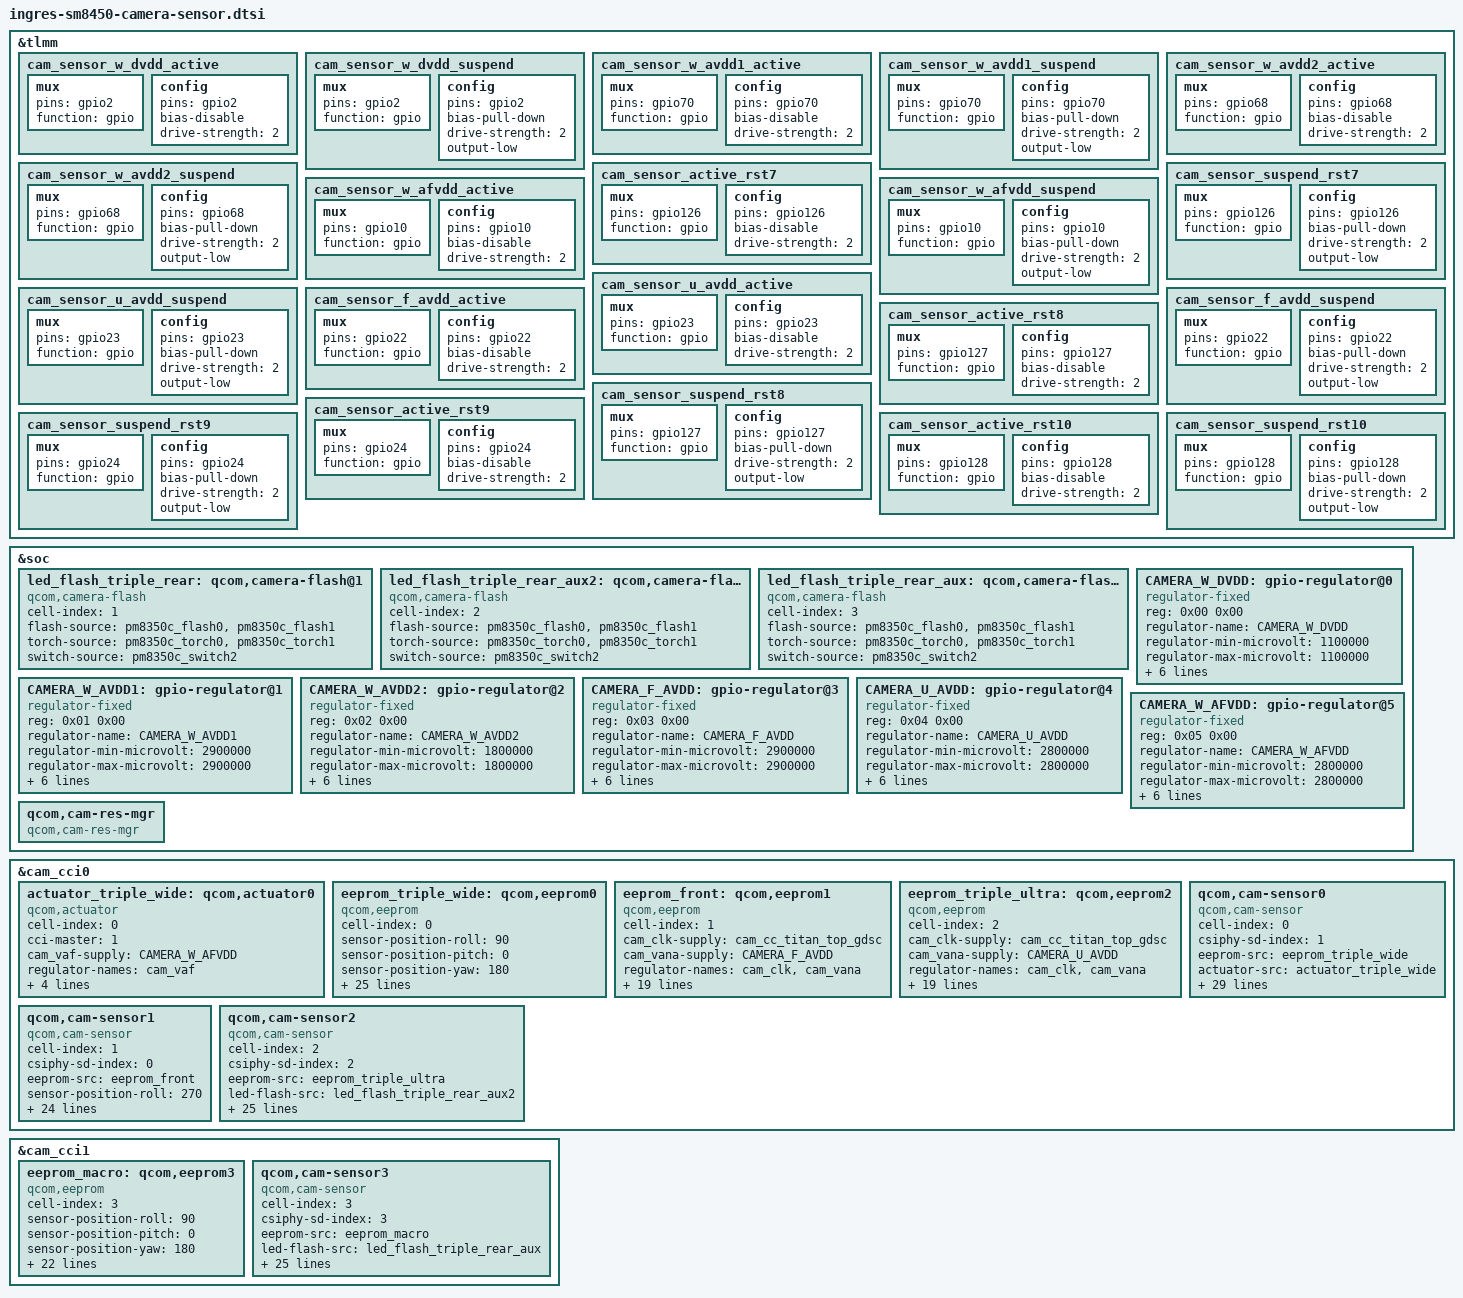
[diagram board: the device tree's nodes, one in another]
#include <dt-bindings/clock/qcom,camcc-waipio.h>

&tlmm {
//wide dvdd
	cam_sensor_w_dvdd_active: cam_sensor_w_dvdd_active {
		/* SENSOR WIDE DVDD ENABLE */
		mux {
			pins = "gpio2";
			function = "gpio";
		};

		config {
			pins = "gpio2";
			bias-disable; /* No PULL */
			drive-strength = <2>; /* 2 MA */
		};
	};

	cam_sensor_w_dvdd_suspend: cam_sensor_w_dvdd_suspend {
		/* SENSOR WIDE DVDD DISABLE */
		mux {
			pins = "gpio2";
			function = "gpio";
		};

		config {
			pins = "gpio2";
			bias-pull-down; /* PULL DOWN */
			drive-strength = <2>; /* 2 MA */
			output-low;
		};
	};

//wide avdd1
	cam_sensor_w_avdd1_active: cam_sensor_w_avdd1_active {
		/* SENSOR WIDE DVDD ENABLE */
		mux {
			pins = "gpio70";
			function = "gpio";
		};

		config {
			pins = "gpio70";
			bias-disable; /* No PULL */
			drive-strength = <2>; /* 2 MA */
		};
	};

	cam_sensor_w_avdd1_suspend: cam_sensor_w_avdd1_suspend {
		/* SENSOR WIDE DVDD DISABLE */
		mux {
			pins = "gpio70";
			function = "gpio";
		};

		config {
			pins = "gpio70";
			bias-pull-down; /* PULL DOWN */
			drive-strength = <2>; /* 2 MA */
			output-low;
		};
	};

//wide avdd2
	cam_sensor_w_avdd2_active: cam_sensor_w_avdd2_active {
		/* SENSOR WIDE DVDD ENABLE */
		mux {
			pins = "gpio68";
			function = "gpio";
		};

		config {
			pins = "gpio68";
			bias-disable; /* No PULL */
			drive-strength = <2>; /* 2 MA */
		};
	};

	cam_sensor_w_avdd2_suspend: cam_sensor_w_avdd2_suspend {
		/* SENSOR WIDE DVDD DISABLE */
		mux {
			pins = "gpio68";
			function = "gpio";
		};

		config {
			pins = "gpio68";
			bias-pull-down; /* PULL DOWN */
			drive-strength = <2>; /* 2 MA */
			output-low;
		};
	};

//wide reset
	cam_sensor_active_rst7: cam_sensor_active_rst7 {
		/* RESET FRONT */
		mux {
			pins = "gpio126";
			function = "gpio";
		};

		config {
			pins = "gpio126";
			bias-disable; /* No PULL */
			drive-strength = <2>; /* 2 MA */
		};
	};

	cam_sensor_suspend_rst7: cam_sensor_suspend_rst7 {
		/* RESET FRONT */
		mux {
			pins = "gpio126";
			function = "gpio";
		};

		config {
			pins = "gpio126";
			bias-pull-down; /* PULL DOWN */
			drive-strength = <2>; /* 2 MA */
			output-low;
		};
	};
//wide  afvdd
	cam_sensor_w_afvdd_active: cam_sensor_w_afvdd_active {
		/* SENSOR FRONT DVDD ENABLE */
		mux {
			pins = "gpio10";
			function = "gpio";
		};

		config {
			pins = "gpio10";
			bias-disable; /* No PULL */
			drive-strength = <2>; /* 2 MA */
		};
	};

	cam_sensor_w_afvdd_suspend: cam_sensor_w_afvdd_suspend {
		/* SENSOR FRONT DVDD DISABLE */
		mux {
			pins = "gpio10";
			function = "gpio";
		};

		config {
			pins = "gpio10";
			bias-pull-down; /* PULL DOWN */
			drive-strength = <2>; /* 2 MA */
			output-low;
		};
	};
	
//front dvdd
	cam_sensor_u_avdd_active: cam_sensor_u_avdd_active {
		/* SENSOR FRONT DVDD ENABLE */
		mux {
			pins = "gpio23";
			function = "gpio";
		};

		config {
			pins = "gpio23";
			bias-disable; /* No PULL */
			drive-strength = <2>; /* 2 MA */
		};
	};

	cam_sensor_u_avdd_suspend: cam_sensor_u_avdd_suspend {
		/* SENSOR FRONT DVDD DISABLE */
		mux {
			pins = "gpio23";
			function = "gpio";
		};

		config {
			pins = "gpio23";
			bias-pull-down; /* PULL DOWN */
			drive-strength = <2>; /* 2 MA */
			output-low;
		};
	};

//front avdd
	cam_sensor_f_avdd_active: cam_sensor_f_avdd_active {
		/* SENSOR FRONT AVDD ENABLE */
		mux {
			pins = "gpio22";
			function = "gpio";
		};

		config {
			pins = "gpio22";
			bias-disable; /* No PULL */
			drive-strength = <2>; /* 2 MA */
		};
	};

	cam_sensor_f_avdd_suspend: cam_sensor_f_avdd_suspend {
		/* SENSOR FRONT AVDD DISABLE */
		mux {
			pins = "gpio22";
			function = "gpio";
		};

		config {
			pins = "gpio22";
			bias-pull-down; /* PULL DOWN */
			drive-strength = <2>; /* 2 MA */
			output-low;
		};
	};

//front reset
	cam_sensor_active_rst8: cam_sensor_active_rst8 {
		/* RESET FRONT */
		mux {
			pins = "gpio127";
			function = "gpio";
		};

		config {
			pins = "gpio127";
			bias-disable; /* No PULL */
			drive-strength = <2>; /* 2 MA */
		};
	};

	cam_sensor_suspend_rst8: cam_sensor_suspend_rst8 {
		/* RESET FRONT */
		mux {
			pins = "gpio127";
			function = "gpio";
		};

		config {
			pins = "gpio127";
			bias-pull-down; /* PULL DOWN */
			drive-strength = <2>; /* 2 MA */
			output-low;
		};
	};

//ultra reset
	cam_sensor_active_rst9: cam_sensor_active_rst9 {
		/* RESET FRONT */
		mux {
			pins = "gpio24";
			function = "gpio";
		};

		config {
			pins = "gpio24";
			bias-disable; /* No PULL */
			drive-strength = <2>; /* 2 MA */
		};
	};

	cam_sensor_suspend_rst9: cam_sensor_suspend_rst9 {
		/* RESET FRONT */
		mux {
			pins = "gpio24";
			function = "gpio";
		};

		config {
			pins = "gpio24";
			bias-pull-down; /* PULL DOWN */
			drive-strength = <2>; /* 2 MA */
			output-low;
		};
	};

//macro reset
	cam_sensor_active_rst10: cam_sensor_active_rst10 {
		/* RESET REARAUX */
		mux {
			pins = "gpio128";
			function = "gpio";
		};

		config {
			pins = "gpio128";
			bias-disable; /* No PULL */
			drive-strength = <2>; /* 2 MA */
		};
	};

	cam_sensor_suspend_rst10: cam_sensor_suspend_rst10 {
		/* RESET REARAUX */
		mux {
			pins = "gpio128";
			function = "gpio";
		};

		config {
			pins = "gpio128";
			bias-pull-down; /* PULL DOWN */
			drive-strength = <2>; /* 2 MA */
			output-low;
		};
	};
};

&soc {
	led_flash_triple_rear: qcom,camera-flash@1 {
		cell-index = <1>;
		compatible = "qcom,camera-flash";
		flash-source = <&pm8350c_flash0 &pm8350c_flash1>;
		torch-source = <&pm8350c_torch0 &pm8350c_torch1>;
		switch-source = <&pm8350c_switch2>;
		status = "ok";
	};

	led_flash_triple_rear_aux2: qcom,camera-flash@2 {
		cell-index = <2>;
		compatible = "qcom,camera-flash";
		flash-source = <&pm8350c_flash0 &pm8350c_flash1>;
		torch-source = <&pm8350c_torch0 &pm8350c_torch1>;
		switch-source = <&pm8350c_switch2>;
		status = "ok";
	};

	led_flash_triple_rear_aux: qcom,camera-flash@3 {
		cell-index = <3>;
		compatible = "qcom,camera-flash";
		flash-source = <&pm8350c_flash0 &pm8350c_flash1>;
		torch-source = <&pm8350c_torch0 &pm8350c_torch1>;
		switch-source = <&pm8350c_switch2>;
		status = "ok";
	};


	CAMERA_W_DVDD: gpio-regulator@0 {
		compatible = "regulator-fixed";
		reg = <0x00 0x00>;
		regulator-name = "CAMERA_W_DVDD";
		regulator-min-microvolt = <1100000>;
		regulator-max-microvolt = <1100000>;
		regulator-enable-ramp-delay = <100>;
		enable-active-high;
		gpio = <&tlmm 2 0>;
		pinctrl-names = "default", "sleep";
		pinctrl-0 = <&cam_sensor_w_dvdd_active &cam_sensor_w_dvdd_suspend>;
		vin-supply = <&S12B>;
	};

	CAMERA_W_AVDD1: gpio-regulator@1 {
		compatible = "regulator-fixed";
		reg = <0x01 0x00>;
		regulator-name = "CAMERA_W_AVDD1";
		regulator-min-microvolt = <2900000>;
		regulator-max-microvolt = <2900000>;
		regulator-enable-ramp-delay = <100>;
		enable-active-high;
		gpio = <&tlmm 70 0>;
		pinctrl-names = "default", "sleep";
		pinctrl-0 = <&cam_sensor_w_avdd1_active &cam_sensor_w_avdd1_suspend>;
		vin-supply = <&BOB>;
	};

	CAMERA_W_AVDD2: gpio-regulator@2 {
		compatible = "regulator-fixed";
		reg = <0x02 0x00>;
		regulator-name = "CAMERA_W_AVDD2";
		regulator-min-microvolt = <1800000>;
		regulator-max-microvolt = <1800000>;
		regulator-enable-ramp-delay = <100>;
		enable-active-high;
		gpio = <&tlmm 68 0>;
		pinctrl-names = "default", "sleep";
		pinctrl-0 = <&cam_sensor_w_avdd2_active &cam_sensor_w_avdd2_suspend>;
		vin-supply = <&BOB>;
	};

	CAMERA_F_AVDD: gpio-regulator@3 {
		compatible = "regulator-fixed";
		reg = <0x03 0x00>;
		regulator-name = "CAMERA_F_AVDD";
		regulator-min-microvolt = <2900000>;
		regulator-max-microvolt = <2900000>;
		regulator-enable-ramp-delay = <100>;
		enable-active-high;
		gpio = <&tlmm 22 0>;
		pinctrl-names = "default", "sleep";
		pinctrl-0 = <&cam_sensor_f_avdd_active &cam_sensor_f_avdd_suspend>;
		vin-supply = <&BOB>;
	};

	CAMERA_U_AVDD: gpio-regulator@4 {
		compatible = "regulator-fixed";
		reg = <0x04 0x00>;
		regulator-name = "CAMERA_U_AVDD";
		regulator-min-microvolt = <2800000>;
		regulator-max-microvolt = <2800000>;
		regulator-enable-ramp-delay = <100>;
		enable-active-high;
		gpio = <&tlmm 23 0>;
		pinctrl-names = "default", "sleep";
		pinctrl-0 = <&cam_sensor_u_avdd_active &cam_sensor_u_avdd_suspend>;
		vin-supply = <&BOB>;
	};

	CAMERA_W_AFVDD: gpio-regulator@5 {
		compatible = "regulator-fixed";
		reg = <0x05 0x00>;
		regulator-name = "CAMERA_W_AFVDD";
		regulator-min-microvolt = <2800000>;
		regulator-max-microvolt = <2800000>;
		regulator-enable-ramp-delay = <100>;
		enable-active-high;
		gpio = <&tlmm 10 0>;
		pinctrl-names = "default", "sleep";
		pinctrl-0 = <&cam_sensor_w_afvdd_active &cam_sensor_w_afvdd_suspend>;
		vin-supply = <&BOB>;
	};

	qcom,cam-res-mgr {
		compatible = "qcom,cam-res-mgr";
		status = "ok";
	};
};

&cam_cci0
{
	actuator_triple_wide: qcom,actuator0 {
		cell-index = <0>;
		compatible = "qcom,actuator";
		cci-master = <1>;
		cam_vaf-supply = <&CAMERA_W_AFVDD>;
		regulator-names = "cam_vaf";
		rgltr-cntrl-support;
		rgltr-min-voltage = <2800000>;
		rgltr-max-voltage = <2800000>;
		rgltr-load-current = <103000>;
	};

	eeprom_triple_wide:qcom,eeprom0 {
		cell-index = <0>;
		compatible = "qcom,eeprom";
		sensor-position-roll = <90>;
		sensor-position-pitch = <0>;
		sensor-position-yaw = <180>;
		//cam_vio-supply = <&L5J>;
		cam_vdig-supply = <&CAMERA_W_DVDD>;
		cam_clk-supply = <&cam_cc_titan_top_gdsc>;
		cam_vana-supply = <&CAMERA_W_AVDD1>;
		cam_v_custom1-supply = <&CAMERA_W_AVDD2>;
		regulator-names = "cam_vdig",
			"cam_clk", "cam_vana", "cam_v_custom1";
		rgltr-cntrl-support;
		rgltr-min-voltage = <1100000 0 2900000 1800000>;
		rgltr-max-voltage = <1100000 0 2900000 1800000>;
		rgltr-load-current = <872000 0 100000 100000>;
		gpio-no-mux = <0>;
		pinctrl-names = "cam_default", "cam_suspend";
		pinctrl-0 = <&cam_sensor_mclk2_active
			&cam_sensor_active_rst7>;
		pinctrl-1 = <&cam_sensor_mclk2_suspend
			&cam_sensor_suspend_rst7>;
		gpios = <&tlmm 102 0>,
			<&tlmm 126 0>;
		gpio-reset = <1>;
		gpio-req-tbl-num = <0 1>;
		gpio-req-tbl-flags = <1 0>;
		gpio-req-tbl-label = "CAMIF_MCLK2",
					"CAM_RESET7";
		cci-device = <0>;
		cci-master = <1>;
		clocks = <&clock_camcc CAM_CC_MCLK2_CLK>;
		clock-names = "cam_clk";
		clock-cntl-level = "nominal";
		clock-rates = <19200000>;
		status = "ok";
	};

	eeprom_front: qcom,eeprom1 {                                     //front imx596
		cell-index = <1>;
		compatible = "qcom,eeprom";
		//cam_vio-supply = <&L5J>;
		//cam_vdig-supply = <&L1J>;
		cam_clk-supply = <&cam_cc_titan_top_gdsc>;
		cam_vana-supply = <&CAMERA_F_AVDD>;
		regulator-names = "cam_clk", "cam_vana";
		rgltr-cntrl-support;
		rgltr-min-voltage = <0 2900000>;
		rgltr-max-voltage = <0 2900000>;
		rgltr-load-current = <0 35000>;
		gpio-no-mux = <0>;
		pinctrl-names = "cam_default", "cam_suspend";
		pinctrl-0 = <&cam_sensor_mclk5_active
			&cam_sensor_active_rst8>;
		pinctrl-1 = <&cam_sensor_mclk5_suspend
			&cam_sensor_suspend_rst8>;
		gpios = <&tlmm 105 0>,
			<&tlmm 127 0>;
		gpio-reset = <1>;
		gpio-req-tbl-num = <0 1>;
		gpio-req-tbl-flags = <1 0>;
		gpio-req-tbl-label = "CAMIF_MCLK5",
					"CAM_RESET8";
		cci-device = <0>;
		cci-master = <0>;
		clocks = <&clock_camcc CAM_CC_MCLK5_CLK>;
		clock-names = "cam_clk";
		clock-cntl-level = "nominal";
		clock-rates = <19200000>;
		status = "ok";
	};

	eeprom_triple_ultra: qcom,eeprom2 {                           //ov8856
		cell-index = <2>;
		compatible = "qcom,eeprom";
		//cam_vio-supply = <&L5J>;
		//cam_vdig-supply = <&L2J>;
		cam_clk-supply = <&cam_cc_titan_top_gdsc>;
		cam_vana-supply = <&CAMERA_U_AVDD>;
		//cam_v_custom1-supply = <&L7J>;
		regulator-names = "cam_clk", "cam_vana";
		rgltr-cntrl-support;
		rgltr-min-voltage = <0 2800000>;
		rgltr-max-voltage = <0 2800000>;
		rgltr-load-current = <0 35000>;
		gpio-no-mux = <0>;
		pinctrl-names = "cam_default", "cam_suspend";
		pinctrl-0 = <&cam_sensor_mclk1_active
			&cam_sensor_active_rst9>;
		pinctrl-1 = <&cam_sensor_mclk1_suspend
			&cam_sensor_suspend_rst9>;
		gpios = <&tlmm 101 0>,
			<&tlmm 24 0>;
		gpio-reset = <1>;
		gpio-req-tbl-num = <0 1>;
		gpio-req-tbl-flags = <1 0>;
		gpio-req-tbl-label = "CAMIF_MCLK1",
					"CAM_RESET9";
		cci-device = <0>;
		cci-master = <0>;
		clocks = <&clock_camcc CAM_CC_MCLK1_CLK>;
		clock-names = "cam_clk";
		clock-cntl-level = "nominal";
		clock-rates = <19200000>;
		status = "ok";
	};

	qcom,cam-sensor0 {                                     //wide imx686
		cell-index = <0>;
		compatible = "qcom,cam-sensor";
		csiphy-sd-index = <1>;
		eeprom-src = <&eeprom_triple_wide>;
		actuator-src = <&actuator_triple_wide>;
		led-flash-src = <&led_flash_triple_rear>;
		sensor-position-roll = <90>;
		sensor-position-pitch = <0>;
		sensor-position-yaw = <180>;
		//cam_vio-supply = <&L5J>;
		cam_vdig-supply = <&CAMERA_W_DVDD>;
		cam_clk-supply = <&cam_cc_titan_top_gdsc>;
		cam_vana-supply = <&CAMERA_W_AVDD1>;
		cam_v_custom1-supply = <&CAMERA_W_AVDD2>;
		regulator-names = "cam_vdig",
			"cam_clk", "cam_vana", "cam_v_custom1";
		rgltr-cntrl-support;
		rgltr-min-voltage = <1100000 0 2900000 1800000>;
		rgltr-max-voltage = <1100000 0 2900000 1800000>;
		rgltr-load-current = <872000 0 100000 100000>;
		gpio-no-mux = <0>;
		pinctrl-names = "cam_default", "cam_suspend";
		pinctrl-0 = <&cam_sensor_mclk2_active
			&cam_sensor_active_rst7>;
		pinctrl-1 = <&cam_sensor_mclk2_suspend
			&cam_sensor_suspend_rst7>;
		gpios = <&tlmm 102 0>,
			<&tlmm 126 0>;
		gpio-reset = <1>;
		gpio-req-tbl-num = <0 1>;
		gpio-req-tbl-flags = <1 0>;
		gpio-req-tbl-label = "CAMIF_MCLK2",
					"CAM_RESET7";
		cci-device = <0>;
		cci-master = <1>;
		clocks = <&clock_camcc CAM_CC_MCLK2_CLK>;
		clock-names = "cam_clk";
		clock-cntl-level = "nominal";
		clock-rates = <19200000>;
		status = "ok";
	};

	qcom,cam-sensor1 {                                     //front imx596
		cell-index = <1>;
		compatible = "qcom,cam-sensor";
		csiphy-sd-index = <0>;
		eeprom-src = <&eeprom_front>;
		sensor-position-roll = <270>;
		sensor-position-pitch = <0>;
		sensor-position-yaw = <0>;
		//cam_vio-supply = <&L5J>;
		//cam_vdig-supply = <&L1J>;
		cam_clk-supply = <&cam_cc_titan_top_gdsc>;
		cam_vana-supply = <&CAMERA_F_AVDD>;
		regulator-names = "cam_clk", "cam_vana";
		rgltr-cntrl-support;
		rgltr-min-voltage = <0 2900000>;
		rgltr-max-voltage = <0 2900000>;
		rgltr-load-current = <0 35000>;
		gpio-no-mux = <0>;
		pinctrl-names = "cam_default", "cam_suspend";
		pinctrl-0 = <&cam_sensor_mclk5_active
			&cam_sensor_active_rst8>;
		pinctrl-1 = <&cam_sensor_mclk5_suspend
			&cam_sensor_suspend_rst8>;
		gpios = <&tlmm 105 0>,
			<&tlmm 127 0>;
		gpio-reset = <1>;
		gpio-req-tbl-num = <0 1>;
		gpio-req-tbl-flags = <1 0>;
		gpio-req-tbl-label = "CAMIF_MCLK5",
					"CAM_RESET8";
		cci-device = <0>;
		cci-master = <0>;
		clocks = <&clock_camcc CAM_CC_MCLK5_CLK>;
		clock-names = "cam_clk";
		clock-cntl-level = "nominal";
		clock-rates = <19200000>;
		status = "ok";
	};

	qcom,cam-sensor2 {                                   //ultra ov8856
		cell-index = <2>;
		compatible = "qcom,cam-sensor";
		csiphy-sd-index = <2>;
		eeprom-src = <&eeprom_triple_ultra>;
		led-flash-src = <&led_flash_triple_rear_aux2>;
		sensor-position-roll = <90>;
		sensor-position-pitch = <0>;
		sensor-position-yaw = <180>;
		//cam_vio-supply = <&L5J>;
		//cam_vdig-supply = <&L2J>;
		cam_clk-supply = <&cam_cc_titan_top_gdsc>;
		cam_vana-supply = <&CAMERA_U_AVDD>;
		//cam_v_custom1-supply = <&L7J>;
		regulator-names = "cam_clk", "cam_vana";
		rgltr-cntrl-support;
		rgltr-min-voltage = <0 2800000>;
		rgltr-max-voltage = <0 2800000>;
		rgltr-load-current = <0 35000>;
		gpio-no-mux = <0>;
		pinctrl-names = "cam_default", "cam_suspend";
		pinctrl-0 = <&cam_sensor_mclk1_active
			&cam_sensor_active_rst9>;
		pinctrl-1 = <&cam_sensor_mclk1_suspend
			&cam_sensor_suspend_rst9>;
		gpios = <&tlmm 101 0>,
			<&tlmm 24 0>;
		gpio-reset = <1>;
		gpio-req-tbl-num = <0 1>;
		gpio-req-tbl-flags = <1 0>;
		gpio-req-tbl-label = "CAMIF_MCLK1",
					"CAM_RESET9";
		cci-device = <0>;
		cci-master = <0>;
		clocks = <&clock_camcc CAM_CC_MCLK1_CLK>;
		clock-names = "cam_clk";
		clock-cntl-level = "nominal";
		clock-rates = <19200000>;
		status = "ok";
	};
};

&cam_cci1 {
	eeprom_macro: qcom,eeprom3 {
		cell-index = <3>;
		compatible = "qcom,eeprom";
		sensor-position-roll = <90>;
		sensor-position-pitch = <0>;
		sensor-position-yaw = <180>;
		//cam_vio-supply = <&L6J>;
		cam_clk-supply = <&cam_cc_titan_top_gdsc>;
		cam_vana-supply = <&CAMERA_U_AVDD>;
		regulator-names = "cam_clk", "cam_vana";
		rgltr-cntrl-support;
		rgltr-min-voltage = <0 2800000>;
		rgltr-max-voltage = <0 2800000>;
		rgltr-load-current = <0 40000>;
		gpio-no-mux = <0>;
		pinctrl-names = "cam_default", "cam_suspend";
		pinctrl-0 = <&cam_sensor_mclk0_active
			&cam_sensor_active_rst10>;
		pinctrl-1 = <&cam_sensor_mclk0_suspend
			&cam_sensor_suspend_rst10>;
		gpios = <&tlmm 100 0>,
			<&tlmm 128 0>;
		gpio-reset = <1>;
		gpio-req-tbl-num = <0 1>;
		gpio-req-tbl-flags = <1 0>;
		gpio-req-tbl-label = "CAMIF_MCLK0",
					"CAM_RESET10";
		cci-device = <1>;
		cci-master = <0>;
		clocks = <&clock_camcc CAM_CC_MCLK0_CLK>;
		clock-names = "cam_clk";
		clock-cntl-level = "nominal";
		clock-rates = <19200000>;
		status = "ok";
	};

	qcom,cam-sensor3 {                                    //macro gc02m1
		cell-index = <3>;
		compatible = "qcom,cam-sensor";
		csiphy-sd-index = <3>;
		eeprom-src = <&eeprom_macro>;
		led-flash-src = <&led_flash_triple_rear_aux>;
		sensor-position-roll = <90>;
		sensor-position-pitch = <0>;
		sensor-position-yaw = <180>;
		//cam_vio-supply = <&L6J>;
		cam_clk-supply = <&cam_cc_titan_top_gdsc>;
		cam_vana-supply = <&CAMERA_U_AVDD>;
		regulator-names = "cam_clk", "cam_vana";
		rgltr-cntrl-support;
		rgltr-min-voltage = <0 2800000>;
		rgltr-max-voltage = <0 2800000>;
		rgltr-load-current = <0 40000>;
		gpio-no-mux = <0>;
		pinctrl-names = "cam_default", "cam_suspend";
		pinctrl-0 = <&cam_sensor_mclk0_active
			&cam_sensor_active_rst10>;
		pinctrl-1 = <&cam_sensor_mclk0_suspend
			&cam_sensor_suspend_rst10>;
		gpios = <&tlmm 100 0>,
			<&tlmm 128 0>;
		gpio-reset = <1>;
		gpio-req-tbl-num = <0 1>;
		gpio-req-tbl-flags = <1 0>;
		gpio-req-tbl-label = "CAMIF_MCLK0",
					"CAM_RESET10";
		cci-device = <1>;
		cci-master = <0>;
		clocks = <&clock_camcc CAM_CC_MCLK0_CLK>;
		clock-names = "cam_clk";
		clock-cntl-level = "nominal";
		clock-rates = <19200000>;
		status = "ok";
	};
};
